# IWRL6432 register map
File version: 1.0
CPU: CM4 1.0, other endian, MPU, FPU, 3 interrupt priority bits
Registers are 32-bit, read-write, reset 0x0 unless marked. A register's access mark holds for its fields unless they carry their own. Offsets are from the block's base; [hi:lo] are bit positions; {n}, {i} and the like mark numbered series.

## APP_PWM (part 1 of 2)
Base 0x57F7FC00
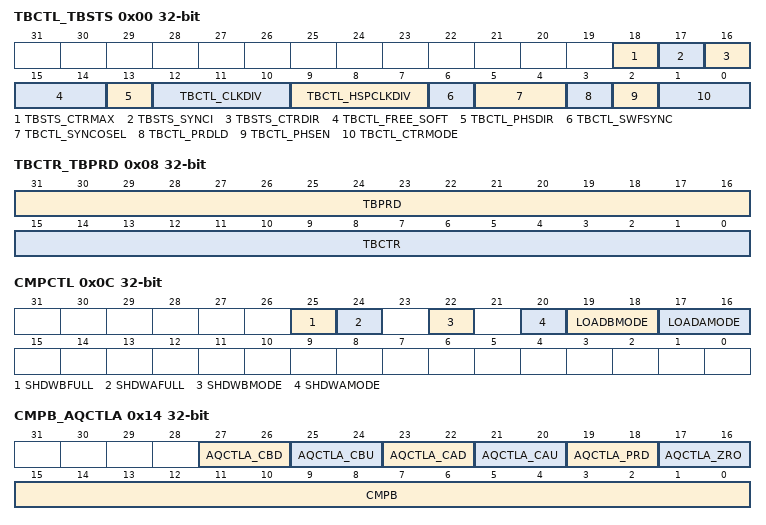
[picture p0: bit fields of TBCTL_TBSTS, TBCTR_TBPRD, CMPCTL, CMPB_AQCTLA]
0x00 TBCTL_TBSTS — Time-Base Control Register/ Status Register
  [18] TBSTS_CTRMAX — [18:18] Time-Base Counter Max Latched Status Bit 0 Read: Indicates the time-base counter never reached its maximum value. Write: No effect. 1 Read: Indicates that the time-base counter reached the maximum value 0xFFFF. Write: Clears the latched event.
  [17] TBSTS_SYNCI — [17:17] Input Synchronization Latched Status Bit 0 Read: Indicates no external synchronization event has occurred. Write: No effect. 1 Read: Indicates that an external synchronization event has occurred (EPWMxSYNCI). Write: Clears the latched event.
  [16] TBSTS_CTRDIR — [16:16] Time-Base Counter Direction Status Bit. At reset, the counter is frozen; therefore, this bit has no meaning. To make this bit meaningful, you must first set the appropriate mode via TBCTL[CTRMODE]. 0 Time-Base Counter is currently counting down. 1 Time-Base Counter is currently counting up.
  [15:14] TBCTL_FREE_SOFT — [15:14] Emulation Mode Bits. These bits select the behavior of the ePWM time-base counter during emulation events: 0 Stop after the next time-base counter increment or decrement 1h Stop when counter completes a whole cycle: ΓÇó Up-count mode: stop when the time-base counter = period (TBCTR = TBPRD) ΓÇó Down-count mode: stop when the time-base counter = 0x0000 (TBCTR = 0x0000) ΓÇó Up-down-count mode: stop when the time-base counter = 0x0000 (TBCTR = 0x0000) 2h-3h Free run
  [13] TBCTL_PHSDIR — [13:13] Phase Direction Bit. This bit is only used when the time-base counter is configured in the up-down-count mode. The PHSDIR bit indicates the direction the time-base counter (TBCTR) will count after a synchronization event occurs and a new phase value is loaded from the phase (TBPHS) register. This is irrespective of the direction of the counter before the synchronization event.. In the up-count and down-count modes this bit is ignored. 0 Count down after the synchronization event. 1 Count up after the synchronization event
  [12:10] TBCTL_CLKDIV — [12:10] Time-base Clock Prescale Bits These bits determine part of the time-base clock prescale value. TBCLK = VCLK3 / (HSPCLKDIV ∩┐╜ CLKDIV) 0 /1 (default on reset) 1h /2 2h /4 3h /8 4h /16 5h /32 6h /64 7h /128
  [9:7] TBCTL_HSPCLKDIV — [9:7] High Speed Time-base Clock Prescale Bits. These bits determine part of the time-base clock prescale value: TBCLK = VCLK3 / (HSPCLKDIV ∩┐╜ CLKDIV) 0 /1 1h /2 (default on reset) 2h /4 3h /6 4h /8 5h /10 6h /12 7h /14
  [6] TBCTL_SWFSYNC — [6:6] Software Forced Synchronization Pulse 0 Writing a 0 has no effect and reads always return a 0. 1 Writing a 1 forces a one-time synchronization pulse to be generated. This event is ORed with the EPWMxSYNCI input of the ePWM module. SWFSYNC is valid (operates) only when EPWMxSYNCI is selected by SYNCOSEL = 00.
  [5:4] TBCTL_SYNCOSEL — [5:4] Synchronization Output Select. These bits select the source of the EPWMxSYNCO signal. 0 EPWMxSYNC: 1h CTR = zero: Time-base counter equal to zero (TBCTR = 0x0000) 2h CTR = CMPB : Time-base counter equal to counter-compare B (TBCTR = CMPB) 3h Disable EPWMxSYNCO signal
  [3] TBCTL_PRDLD — [3:3] Active Period Register Load From Shadow Register Select 0 The period register (TBPRD) is loaded from its shadow register when the time-base counter, TBCTR, is equal to zero. A write or read to the TBPRD register accesses the shadow register. 1 Load the TBPRD register immediately without using a shadow register. A write or read to the TBPRD register directly accesses the active register.
  [2] TBCTL_PHSEN — [2:2] Counter Register Load From Phase Register Enable 0 Do not load the time-base counter (TBCTR) from the time-base phase register (TBPHS) 1 Load the time-base counter with the phase register when an EPWMxSYNCI input signal occurs or when a software synchronization is forced by the SWFSYNC bit, or when a digital compare sync event occurs.
  [1:0] TBCTL_CTRMODE — [1:0] Counter Mode The time-base counter mode is normally configured once and not changed during normal operation. If you change the mode of the counter, the change will take effect at the next TBCLK edge and the current counter value shall increment or decrement from the value before the mode change. These bits set the time-base counter mode of operation as follows: 0 Up-count mode 1h Down-count mode 2h Up-down-count mode 3h Stop-freeze counter operation (default on reset)
0x04 TBPHS — Time-Base Phase Register
  [31:16] TBPHS — [31:16] Time-Base Phase Register These bits set time-base counter phase of the selected ePWM relative to the time-base that is supplying the synchronization input signal. ΓÇó If TBCTL[PHSEN] = 0, then the synchronization event is ignored and the time-base counter is not loaded with the phase. ΓÇó If TBCTL[PHSEN] = 1, then the time-base counter (TBCTR) will be loaded with the phase (TBPHS) when a synchronization event occurs. The synchronization event can be initiated by the input synchronization signal (EPWMxSYNCI) or by a software forced synchronization.
0x08 TBCTR_TBPRD — Time-Base Counter Register/ Period Register
  [31:16] TBPRD — [31:16] Time-Base Period Register These bits determine the period of the time-base counter. This sets the PWM frequency. Shadowing of this register is enabled and disabled by the TBCTL[PRDLD] bit. By default this register is shadowed. ΓÇó If TBCTL[PRDLD] = 0, then the shadow is enabled and any write or read will automatically go to the shadow register. In this case, the active register will be loaded from the shadow register when the timebase counter equals zero. ΓÇó If TBCTL[PRDLD] = 1, then the shadow is disabled and any write or read will go directly to the active register, that is the register actively controlling the hardware. ΓÇó The active and shadow registers share the same memory map address.
  [15:0] TBCTR — [15:0] Time-Base Counter Register Reading these bits gives the current time-base counter value. Writing to these bits sets the current time-base counter value. The update happens as soon as the write occurs; the write is NOT synchronized to the time-base clock (TBCLK) and the register is not shadowed.
0x0C CMPCTL — Counter-Compare Control Register
  [25] SHDWBFULL — [25:25] Counter-compare B (CMPB) Shadow Register Full Status Flag This bit self clears once a load-strobe occurs. 0 CMPB shadow FIFO not full yet 1 Indicates the CMPB shadow FIFO is full; a CPU write will overwrite current shadow value.
  [24] SHDWAFULL — [24:24] Counter-compare A (CMPA) Shadow Register Full Status Flag The flag bit is set when a 32-bit write to CMPA:CMPAHR register or a 16-bit write to CMPA register is made. A 16-bit write to CMPAHR register will not affect the flag. This bit self clears once a load-strobe occurs. 0 CMPA shadow FIFO not full yet 1 Indicates the CMPA shadow FIFO is full, a CPU write will overwrite the current shadow value
  [22] SHDWBMODE — [22:22] Counter-compare B (CMPB) Register Operating Mode 0 Shadow mode. Operates as a double buffer. All writes via the CPU access the shadow register. 1 Immediate mode. Only the active compare B register is used. All writes and reads directly access the active register for immediate compare action.
  [20] SHDWAMODE — [20:20] Counter-compare A (CMPA) Register Operating Mode 0 Shadow mode. Operates as a double buffer. All writes via the CPU access the shadow register. 1 Immediate mode. Only the active compare register is used. All writes and reads directly access the active register for immediate compare action
  [19:18] LOADBMODE — [19:18] Active Counter-Compare B (CMPB) Load From Shadow Select Mode This bit has no effect in immediate mode (CMPCTL[SHDWBMODE] = 1). 0 Load on CTR = Zero: Time-base counter equal to zero (TBCTR = 0x0000) 1h Load on CTR = PRD: Time-base counter equal to period (TBCTR = TBPRD) 2h Load on either CTR = Zero or CTR = PRD 3h Freeze (no loads possible)
  [17:16] LOADAMODE — [17:16] Active Counter-Compare A (CMPA) Load From Shadow Select Mode. This bit has no effect in immediate mode (CMPCTL[SHDWAMODE] = 1). 0 Load on CTR = Zero: Time-base counter equal to zero (TBCTR = 0x0000) 1h Load on CTR = PRD: Time-base counter equal to period (TBCTR = TBPRD) 2h Load on either CTR = Zero or CTR = PRD 3h Freeze (no loads possible)
0x10 CMPA — Counter-Compare A Register
  [31:16] CMPA — [31:16] Counter-Compare A Register The value in the active CMPA register is continuously compared to the time-base counter (TBCTR). When the values are equal, the counter-compare module generates a "time-base counter equal to counter compare A" event. This event is sent to the action-qualifier where it is qualified and converted it into one or more actions. These actions can be applied to either the EPWMxA or the EPWMxB output depending on the configuration of the AQCTLA and AQCTLB registers. The actions that can be defined in the AQCTLA and AQCTLB registers include: ΓÇó Do nothing; the event is ignored. ΓÇó Clear: Pull the EPWMxA and/or EPWMxB signal low ΓÇó Set: Pull the EPWMxA and/or EPWMxB signal high ΓÇó Toggle the EPWMxA and/or EPWMxB signal Shadowing of this register is enabled and disabled by the CMPCTL[SHDWAMODE] bit. By default this register is shadowed. ΓÇó If CMPCTL[SHDWAMODE] = 0, then the shadow is enabled and any write or read will automatically go to the shadow register. In this case, the CMPCTL[LOADAMODE] bit field determines which event will load the active register from the shadow register. ΓÇó Before a write, the CMPCTL[SHDWAFULL] bit can be read to determine if the shadow register is currently full. ΓÇó If CMPCTL[SHDWAMODE] = 1, then the shadow register is disabled and any write or read will go directly to the active register, that is the register actively controlling the hardware. ΓÇó In either mode, the active and shadow registers share the same memory map address.
0x14 CMPB_AQCTLA — Counter-Compare B Register/ Action-Qualifier Control Register for Output A (EPWMxA)
  [27:26] AQCTLA_CBD — [27:26] Action when the time-base counter equals the active CMPB register and the counter is decrementing. 0 Do nothing (action disabled) 1h Clear: force EPWMxA output low. 2h Set: force EPWMxA output high. 3h Toggle EPWMxA output: low output signal will be forced high, and a high signal will be forced low
  [25:24] AQCTLA_CBU — [25:24] Action when the counter equals the active CMPB register and the counter is incrementing. 0 Do nothing (action disabled) 1h Clear: force EPWMxA output low. 2h Set: force EPWMxA output high. 3h Toggle EPWMxA output: low output signal will be forced high, and a high signal will be forced low
  [23:22] AQCTLA_CAD — [23:22] Action when the counter equals the active CMPA register and the counter is decrementing. 0 Do nothing (action disabled) 1h Clear: force EPWMxA output low. 2h Set: force EPWMxA output high. 3h Toggle EPWMxA output: low output signal will be forced high, and a high signal will be forced low
  [21:20] AQCTLA_CAU — [21:20] Action when the counter equals the active CMPA register and the counter is incrementing. 0 Do nothing (action disabled) 1h Clear: force EPWMxA output low. 2h Set: force EPWMxA output high. 3h Toggle EPWMxA output: low output signal will be forced high, and a high signal will be forced low
  [19:18] AQCTLA_PRD — [19:18] Action when the counter equals the period. Note: By definition, in count up-down mode when the counter equals period the direction is defined as 0 or counting down. 0 Do nothing (action disabled) 1h Clear: force EPWMxA output low. 2h Set: force EPWMxA output high. 3h Toggle EPWMxA output: low output signal will be forced high, and a high signal will be forced low
  [17:16] AQCTLA_ZRO — [17:16] Action when counter equals zero. Note: By definition, in count up-down mode when the counter equals 0 the direction is defined as 1 or counting up. 0 Do nothing (action disabled) 1h Clear: force EPWMxA output low. 2h Set: force EPWMxA output high. 3h Toggle EPWMxA output: low output signal will be forced high, and a high signal will be forced low
  [15:0] CMPB — [15:0] The value in the active CMPB register is continuously compared to the time-base counter (TBCTR). When the values are equal, the counter-compare module generates a "time-base counter equal to counter compare B" event. This event is sent to the action-qualifier where it is qualified and converted it into one or more actions. These actions can be applied to either the EPWMxA or the EPWMxB output depending on the configuration of the AQCTLA and AQCTLB registers. The actions that can be defined in the AQCTLA and AQCTLB registers include: ΓÇó Do nothing. event is ignored. ΓÇó Clear: Pull the EPWMxA and/or EPWMxB signal low ΓÇó Set: Pull the EPWMxA and/or EPWMxB signal high ΓÇó Toggle the EPWMxA and/or EPWMxB signal Shadowing of this register is enabled and disabled by the CMPCTL[SHDWBMODE] bit. By default this register is shadowed. ΓÇó If CMPCTL[SHDWBMODE] = 0, then the shadow is enabled and any write or read will automatically go to the shadow register. In this case, the CMPCTL[LOADBMODE] bit field determines which event will load the active register from the shadow register: ΓÇó Before a write, the CMPCTL[SHDWBFULL] bit can be read to determine if the shadow register is currently full. ΓÇó If CMPCTL[SHDWBMODE] = 1, then the shadow register is disabled and any write or read will go directly to the active register, that is the register actively controlling the hardware. ΓÇó In either mode, the active and shadow registers share the same memory map address
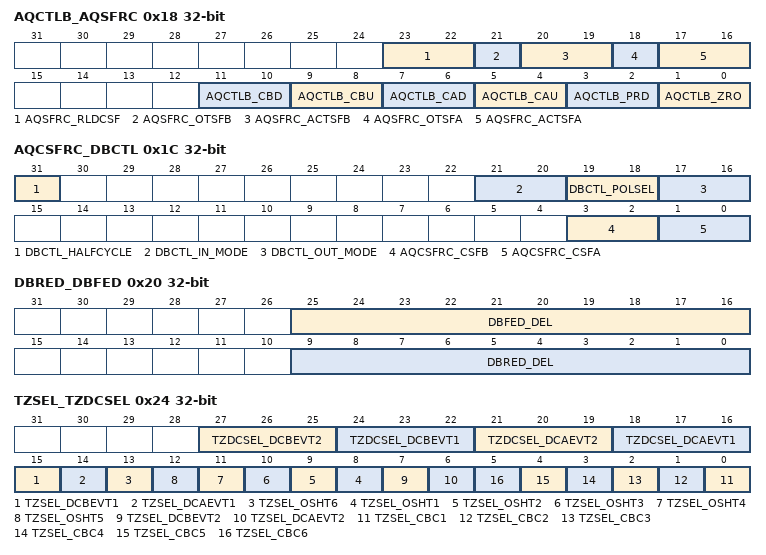
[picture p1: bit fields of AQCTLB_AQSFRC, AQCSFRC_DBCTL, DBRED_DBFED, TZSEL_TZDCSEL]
0x18 AQCTLB_AQSFRC — Action-Qualifier Control Register for Output B (EPWMxB)/ Action-Qualifier Software Force Register
  [23:22] AQSFRC_RLDCSF — [23:22] AQCSFRC Active Register Reload From Shadow Options 0 Load on event counter equals zero 1h Load on event counter equals period 2h Load on event counter equals zero or counter equals period 3h Load immediately (the active register is directly accessed by the CPU and is not loaded from the shadow register).
  [21] AQSFRC_OTSFB — [21:21] One-Time Software Forced Event on Output B 0 Writing a 0 has no effect. Always reads back a 0 This bit is auto cleared once a write to this register is complete (that is, a forced event is initiated.) This is a one-shot forced event. It can be overridden by another subsequent event on output B. 1 Initiates a single s/w forced event
  [20:19] AQSFRC_ACTSFB — [20:19] Action when One-Time Software Force B Is invoked 0 Does nothing (action disabled) 1h Clear (low) 2h Set (high) 3h Toggle (Low -> High, High -> Low) Note: This action is not qualified by counter direction (CNT_dir)
  [18] AQSFRC_OTSFA — [18:18] One-Time Software Forced Event on Output A 0 Writing a 0 has no effect. Always reads back a 0. This bit is auto cleared once a write to this register is complete (that is, a forced event is initiated). 1 Initiates a single software forced event
  [17:16] AQSFRC_ACTSFA — [17:16] Action When One-Time Software Force A Is Invoked 0 Does nothing (action disabled) 1h Clear (low) 2h Set (high) 3h Toggle (Low ΓåÆ High, High ΓåÆ Low) Note: This action is not qualified by counter direction (CNT_dir)
  [11:10] AQCTLB_CBD — [11:10] Action when the counter equals the active CMPB register and the counter is decrementing. 0 Do nothing (action disabled) 1h Clear: force EPWMxB output low. 2h Set: force EPWMxB output high. 3h Toggle EPWMxB output: low output signal will be forced high, and a high signal will be forced low
  [9:8] AQCTLB_CBU — [9:8] Action when the counter equals the active CMPB register and the counter is incrementing. 0 Do nothing (action disabled) 1h Clear: force EPWMxB output low. 2h Set: force EPWMxB output high. 3h Toggle EPWMxB output: low output signal will be forced high, and a high signal will be forced low
  [7:6] AQCTLB_CAD — [7:6] Action when the counter equals the active CMPA register and the counter is decrementing. 0 Do nothing (action disabled) 1h Clear: force EPWMxB output low. 2h Set: force EPWMxB output high. 3h Toggle EPWMxB output: low output signal will be forced high, and a high signal will be forced low
  [5:4] AQCTLB_CAU — [5:4] Action when the counter equals the active CMPA register and the counter is incrementing. 0 Do nothing (action disabled) 1h Clear: force EPWMxB output low. 2h Set: force EPWMxB output high. 3h Toggle EPWMxB output: low output signal will be forced high, and a high signal will be forced low
  [3:2] AQCTLB_PRD — [3:2] Action when the counter equals the period. Note: By definition, in count up-down mode when the counter equals period the direction is defined as 0 or counting down. 0 Do nothing (action disabled) 1h Clear: force EPWMxB output low. 2h Set: force EPWMxB output high. 3h Toggle EPWMxB output: low output signal will be forced high, and a high signal will be forced low
  [1:0] AQCTLB_ZRO — [1:0] Action when counter equals zero. Note: By definition, in count up-down mode when the counter equals 0 the direction is defined as 1 or counting up. 0 Do nothing (action disabled) 1h Clear: force EPWMxB output low. 2h Set: force EPWMxB output high. 3h Toggle EPWMxB output: low output signal will be forced high, and a high signal will be forced low.
0x1C AQCSFRC_DBCTL — Dead-Band Generator Control Register/ Action-Qualifier Continuous S/W Force Register Set
  [31] DBCTL_HALFCYCLE — [31:31] Half Cycle Clocking Enable Bit: 0 Full cycle clocking enabled. The dead-band counters are clocked at the TBCLK rate. 1 Half cycle clocking enabled. The dead-band counters are clocked at TBCLK ∩┐╜ 2.
  [21:20] DBCTL_IN_MODE — [21:20] Dead Band Input Mode Control Bit 5 controls the S5 switch and bit 4 controls the S4 switch shown in Figure 35-28. This allows you to select the input source to the falling-edge and rising-edge delay. To produce classical dead-band waveforms the default is EPWMxA In is the source for both falling and rising-edge delays. 0 EPWMxA In (from the action-qualifier) is the source for both falling-edge and rising-edge delay. 1h EPWMxB In (from the action-qualifier) is the source for rising-edge delayed signal. EPWMxA In (from the action-qualifier) is the source for falling-edge delayed signal. 2h EPWMxA In (from the action-qualifier) is the source for rising-edge delayed signal. EPWMxB In (from the action-qualifier) is the source for falling-edge delayed signal. 3h EPWMxB In (from the action-qualifier) is the source for both rising-edge delay and falling-edge delayed signal.
  [19:18] DBCTL_POLSEL — [19:18] Polarity Select Control Bit 3 controls the S3 switch and bit 2 controls the S2 switch shown in Figure 35-28. This allows you to selectively invert one of the delayed signals before it is sent out of the dead-band submodule. The following descriptions correspond to classical upper/lower switch control as found in one leg of a digital motor control inverter. These assume that DBCTL[OUT_MODE] = 1,1 and DBCTL[IN_MODE] = 0,0. Other enhanced modes are also possible, but not regarded as typical usage modes. 0 Active high (AH) mode. Neither EPWMxA nor EPWMxB is inverted (default). 1h Active low complementary (ALC) mode. EPWMxA is inverted. 2h Active high complementary (AHC). EPWMxB is inverted. 3h Active low (AL) mode. Both EPWMxA and EPWMxB are inverted
  [17:16] DBCTL_OUT_MODE — [17:16] Dead-band Output Mode Control Bit 1 controls the S1 switch and bit 0 controls the S0 switch shown in Figure 35-28. This allows you to selectively enable or bypass the dead-band generation for the falling-edge and rising-edge delay. 0 Dead-band generation is bypassed for both output signals. In this mode, both the EPWMxA and EPWMxB output signals from the action-qualifier are passed directly to the PWM-chopper submodule. In this mode, the POLSEL and IN_MODE bits have no effect. 1h Disable rising-edge delay. The EPWMxA signal from the action-qualifier is passed straight through to the EPWMxA input of the PWM-chopper submodule. The falling-edge delayed signal is seen on output EPWMxB. The input signal for the delay is determined by DBCTL[IN_MODE]. 2h The rising-edge delayed signal is seen on output EPWMxA. The input signal for the delay is determined by DBCTL[IN_MODE]. Disable falling-edge delay. The EPWMxB signal from the action-qualifier is passed straight through to the EPWMxB input of the PWM-chopper submodule. 3h Dead-band is fully enabled for both rising-edge delay on output EPWMxA and falling-edge delay on output EPWMxB. The input signal for the delay is determined by DBCTL[IN_MODE].
  [3:2] AQCSFRC_CSFB — [3:2] Continuous Software Force on Output B In immediate mode, a continuous force takes effect on the next TBCLK edge. In shadow mode, a continuous force takes effect on the next TBCLK edge after a shadow load into the active register. To configure shadow mode, use AQSFRC[RLDCSF]. 0 Forcing disabled, that is, has no effect 1h Forces a continuous low on output B 2h Forces a continuous high on output B 3h Software forcing is disabled and has no effect
  [1:0] AQCSFRC_CSFA — [1:0] Continuous Software Force on Output A In immediate mode, a continuous force takes effect on the next TBCLK edge. In shadow mode, a continuous force takes effect on the next TBCLK edge after a shadow load into the active register. 0 Forcing disabled, that is, has no effect 1h Forces a continuous low on output A 2h Forces a continuous high on output A 3h Software forcing is disabled and has no effect
0x20 DBRED_DBFED — Dead-Band Generator Rising Edge Delay Count Register/ Dead-Band Generator Falling Edge Delay Count Register
  [25:16] DBFED_DEL — [25:16] Falling Edge Delay Count. 10-bit counter
  [9:0] DBRED_DEL — [9:0] Rising Edge Delay Count. 10-bit counter
0x24 TZSEL_TZDCSEL — Trip Zone Digital Compare Select Register/ Trip-Zone Select Register
  [27:25] TZDCSEL_DCBEVT2 — [27:25] Digital Compare Output B Event 2 Selection 0 Event disabled 1h DCBH = low, DCBL = don't care 2h DCBH = high, DCBL = don't care 3h DCBL = low, DCBH = don't care 4h DCBL = high, DCBH = don't care 5h DCBL = high, DCBH = low 6h-7h Reserved
  [24:22] TZDCSEL_DCBEVT1 — [24:22] Digital Compare Output B Event 1 Selection 0 Event disabled 1h DCBH = low, DCBL = don't care 2h DCBH = high, DCBL = don't care 3h DCBL = low, DCBH = don't care 4h DCBL = high, DCBH = don't care 5h DCBL = high, DCBH = low 6h-7h Reserved
  [21:19] TZDCSEL_DCAEVT2 — [21:19] Digital Compare Output A Event 2 Selection 0 Event disabled 1h DCAH = low, DCAL = don't care 2h DCAH = high, DCAL = don't care 3h DCAL = low, DCAH = don't care 4h DCAL = high, DCAH = don't care 5h DCAL = high, DCAH = low 6h-7h Reserved
  [18:16] TZDCSEL_DCAEVT1 — [18:16] Digital Compare Output A Event 1 Selection 0 Event disabled 1h DCAH = low, DCAL = don't care 2h DCAH = high, DCAL = don't care 3h DCAL = low, DCAH = don't care 4h DCAL = high, DCAH = don't care 5h DCAL = high, DCAH = low 6h-7h Reserved
  [15] TZSEL_DCBEVT1 — [15:15] Digital Compare Output B Event 1 Select 0 Disable DCBEVT1 as one-shot-trip source for this ePWM module. 1 Enable DCBEVT1 as one-shot-trip source for this ePWM module
  [14] TZSEL_DCAEVT1 — [14:14] Digital Compare Output A Event 1 Select 0 Disable DCAEVT1 as one-shot-trip source for this ePWM module. 1 Enable DCAEVT1 as one-shot-trip source for this ePWM module
  [13] TZSEL_OSHT6 — [13:13] Trip-zone 6 (TZ6) Select 0 Disable TZ6 as a one-shot trip source for this ePWM module. 1 Enable TZ6 as a one-shot trip source for this ePWM module
  [n+7] TZSEL_OSHT{n} (n=1..5) — [{n+7}:{n+7}] Trip-zone {n} (TZ{n}) Select 0 Disable TZ{n} as a one-shot trip source for this ePWM module 1 Enable TZ{n} as a one-shot trip source for this ePWM module
  [7] TZSEL_DCBEVT2 — [7:7] Digital Compare Output B Event 2 Select 0 Disable DCBEVT2 as a CBC trip source for this ePWM module 1 Enable DCBEVT2 as a CBC trip source for this ePWM module
  [6] TZSEL_DCAEVT2 — [6:6] Digital Compare Output A Event 2 Select 0 Disable DCAEVT2 as a CBC trip source for this ePWM module 1 Enable DCAEVT2 as a CBC trip source for this ePWM module
  [n-1] TZSEL_CBC{n} (n=1..6) — [{n-1}:{n-1}] Trip-zone {n} (TZ{n}) Select 0 Disable TZ{n} as a CBC trip source for this ePWM module 1 Enable TZ{n} as a CBC trip source for this ePWM module
